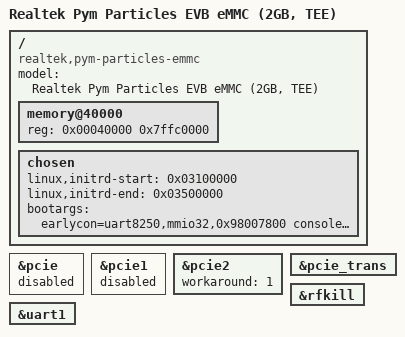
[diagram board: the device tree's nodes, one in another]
// SPDX-License-Identifier: (GPL-2.0-or-later OR BSD-2-Clause)
/*
 * Copyright (c) 2019-2020 Realtek Semiconductor Corp.
 */

/dts-v1/;

#include "rtd1319-pymparticles.dtsi"

/ {
	compatible = "realtek,pym-particles-emmc", "realtek,rtd1319";
	model = "Realtek Pym Particles EVB eMMC (2GB, TEE)";

	memory@40000 {
		device_type = "memory";
		reg = <0x00040000 0x7ffc0000>; /* 2 GiB */
	};

	chosen {
		linux,initrd-start = <0x03100000>;
		linux,initrd-end = <0x03500000>;
		bootargs = "earlycon=uart8250,mmio32,0x98007800 console=ttyS0,460800 uio_pdrv_genirq.of_id=generic-uio init=/sbin/init root=/dev/mmcblk0p1 rootfstype=squashfs rootwait loglevel=8 NO_RESERVE";
	};
};

&pcie {
	status = "disabled";
};

&pcie1 {
	status = "disabled";
};

&pcie2 {
	workaround = <1>;
	status = "okay";
};

&pcie_trans {
	status = "okay";
};

&rfkill {
	status = "okay";
};

&uart1 {
	status = "okay";
};

